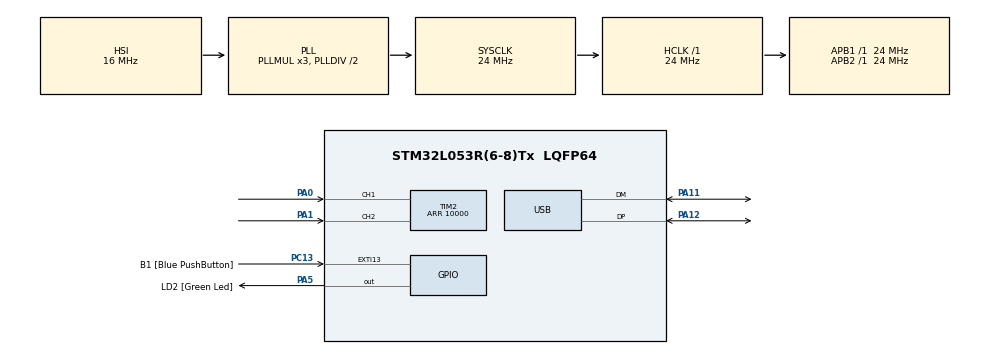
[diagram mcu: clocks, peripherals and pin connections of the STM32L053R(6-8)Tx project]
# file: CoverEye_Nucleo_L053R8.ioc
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Mcu.Family=STM32L0
Mcu.Name=STM32L053R(6-8)Tx
Mcu.Package=LQFP64
NVIC.USB_IRQn=true\:0\:0\:false\:false\:true\:false
PA0.GPIO_PuPd=GPIO_PULLDOWN
PA0.GPIO_Speed=GPIO_SPEED_FREQ_VERY_HIGH
PA0.Signal=S_TIM2_CH1
PA1.GPIO_PuPd=GPIO_PULLDOWN
PA1.GPIO_Speed=GPIO_SPEED_FREQ_VERY_HIGH
PA1.Signal=S_TIM2_CH2
PA11.Mode=Device
PA11.Signal=USB_DM
PA12.Mode=Device
PA12.Signal=USB_DP
PA13.GPIO_Label=TMS
PA13.Signal=SYS_SWDIO
PA14.GPIO_Label=TCK
PA14.Signal=SYS_SWCLK
PA2.GPIO_Label=USART_TX
PA2.Signal=USART2_TX
PA3.GPIO_Label=USART_RX
PA3.Signal=USART2_RX
PA5.GPIO_Label=LD2 [Green Led]
PA5.Signal=GPIO_Output
PC13.GPIO_Label=B1 [Blue PushButton]
PC13.GPIO_ModeDefaultEXTI=GPIO_MODE_IT_FALLING
PC13.Signal=GPXTI13
PC14-OSC32_IN.Signal=RCC_OSC32_IN
PC15-OSC32_OUT.Signal=RCC_OSC32_OUT
PH0-OSC_IN.Signal=RCC_OSC_IN
PH1-OSC_OUT.Signal=RCC_OSC_OUT
ProjectManager.HeapSize=0x200
ProjectManager.StackSize=0x400
ProjectManager.TargetToolchain=SW4STM32
RCC.AHBFreq_Value=24000000
RCC.APB1Freq_Value=24000000
RCC.APB1TimFreq_Value=24000000
RCC.APB2Freq_Value=24000000
RCC.APB2TimFreq_Value=24000000
RCC.HCLKFreq_Value=24000000
RCC.HSE_VALUE=8000000
RCC.HSI16_VALUE=16000000
RCC.HSI48MClockSelection=RCC_USBCLKSOURCE_HSI48
RCC.HSI48_VALUE=48000000
RCC.HSI_VALUE=16000000
RCC.LSEState=RCC_LSE_ON
RCC.LSE_VALUE=32768
RCC.MSI_VALUE=2097000
RCC.SYSCLKFreq_VALUE=24000000
RCC.SYSCLKSource=RCC_SYSCLKSOURCE_PLLCLK
RCC.VCOOutputFreq_Value=48000000
SH.S_TIM2_CH1.0=TIM2_CH1,Encoder_Interface
SH.S_TIM2_CH2.0=TIM2_CH2,Encoder_Interface
TIM2.IC2Filter=0
TIM2.Period=10000
USB_DEVICE.CLASS_NAME_FS=CUSTOMHID
USB_DEVICE.VirtualMode=CustomHid
USB_DEVICE.VirtualModeFS=Custom_Hid_FS
VP_USB_DEVICE_VS_USB_DEVICE_CUSTOM_HID_FS.Mode=CUSTOM_HID_FS
board=NUCLEO-L053R8

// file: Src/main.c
/**
  ******************************************************************************
  * File Name          : main.c
  * Description        : Main program body
  ******************************************************************************
  * This notice applies to any and all portions of this file
  * that are not between comment pairs USER CODE BEGIN and
  * USER CODE END. Other portions of this file, whether
  * inserted by the user or by software development tools
  * are owned by their respective copyright owners.
  *
  * Copyright (c) 2018 STMicroelectronics International N.V.
  * All rights reserved.
  *
  * Redistribution and use in source and binary forms, with or without
  * modification, are permitted, provided that the following conditions are met:
  *
  * 1. Redistribution of source code must retain the above copyright notice,
  *    this list of conditions and the following disclaimer.
  * 2. Redistributions in binary form must reproduce the above copyright notice,
  *    this list of conditions and the following disclaimer in the documentation
  *    and/or other materials provided with the distribution.
  * 3. Neither the name of STMicroelectronics nor the names of other
  *    contributors to this software may be used to endorse or promote products
  *    derived from this software without specific written permission.
  * 4. This software, including modifications and/or derivative works of this
  *    software, must execute solely and exclusively on microcontroller or
  *    microprocessor devices manufactured by or for STMicroelectronics.
  * 5. Redistribution and use of this software other than as permitted under
  *    this license is void and will automatically terminate your rights under
  *    this license.
  *
  * THIS SOFTWARE IS PROVIDED BY STMICROELECTRONICS AND CONTRIBUTORS "AS IS"
  * AND ANY EXPRESS, IMPLIED OR STATUTORY WARRANTIES, INCLUDING, BUT NOT
  * LIMITED TO, THE IMPLIED WARRANTIES OF MERCHANTABILITY, FITNESS FOR A
  * PARTICULAR PURPOSE AND NON-INFRINGEMENT OF THIRD PARTY INTELLECTUAL PROPERTY
  * RIGHTS ARE DISCLAIMED TO THE FULLEST EXTENT PERMITTED BY LAW. IN NO EVENT
  * SHALL STMICROELECTRONICS OR CONTRIBUTORS BE LIABLE FOR ANY DIRECT, INDIRECT,
  * INCIDENTAL, SPECIAL, EXEMPLARY, OR CONSEQUENTIAL DAMAGES (INCLUDING, BUT NOT
  * LIMITED TO, PROCUREMENT OF SUBSTITUTE GOODS OR SERVICES; LOSS OF USE, DATA,
  * OR PROFITS; OR BUSINESS INTERRUPTION) HOWEVER CAUSED AND ON ANY THEORY OF
  * LIABILITY, WHETHER IN CONTRACT, STRICT LIABILITY, OR TORT (INCLUDING
  * NEGLIGENCE OR OTHERWISE) ARISING IN ANY WAY OUT OF THE USE OF THIS SOFTWARE,
  * EVEN IF ADVISED OF THE POSSIBILITY OF SUCH DAMAGE.
  *
  ******************************************************************************
  */

#include "main.h"
#include "stm32l0xx_hal.h"
#include "usb_device.h"
#include "usbd_core.h"
#include "usbd_customhid.h"

TIM_HandleTypeDef htim2;
int count;

// HID testDPControl
  /*struct testDPControlHID_t {
      uint8_t id;
      uint8_t modifiers;
      uint8_t key1;
      uint8_t key2;
      uint8_t key3;
  };*/
//uint8_t *ptestDPControl;
//uint8_t testDPControl=0x777;

  //struct testDPControlHID_t testDPControlHID;

USBD_StatusTypeDef status;
/* USER CODE BEGIN PV */
/* Private variables ---------------------------------------------------------*/

/* USER CODE END PV */

void SystemClock_Config(void);
static void MX_GPIO_Init(void);
static void MX_TIM2_Init(void);

/* USER CODE BEGIN PFP */
/* Private function prototypes -----------------------------------------------*/

/* USER CODE END PFP */

int main(void)
{
	/*testDPControlHID.id = 0x1;
	testDPControlHID.modifiers = 0x2;
	testDPControlHID.key1 = 0x3;
	testDPControlHID.key2 = 0x4;
	testDPControlHID.key3 = 0x5;*/

  /* MCU Configuration----------------------------------------------------------*/

  /* Reset of all peripherals, Initializes the Flash interface and the Systick. */
  HAL_Init();

  /* Configure the system clock */
  SystemClock_Config();

  /* USER CODE BEGIN SysInit */
  //USBD_Init(&hUsbDeviceFS, &FS_Desc, DEVICE_FS);
  //USBD_StatusTypeDef USBD_Init(USBD_HandleTypeDef *pdev, USBD_DescriptorsTypeDef *pdesc, uint8_t id)

  //SBD_RegisterClass(&hUsbDeviceFS, &USBD_CUSTOM_HID);
  //USBD_StatusTypeDef  USBD_RegisterClass(USBD_HandleTypeDef *pdev, USBD_ClassTypeDef *pclass)

  //USBD_CUSTOM_HID_RegisterInterface(&hUsbDeviceFS, &USBD_CustomHID_fops_FS);
  //uint8_t  USBD_CUSTOM_HID_RegisterInterface  (USBD_HandleTypeDef   *pdev,
   //                                            USBD_CUSTOM_HID_ItfTypeDef *fops)

  //USBD_Start(&hUsbDeviceFS);
  /* USER CODE END SysInit */

  /* Initialize all configured peripherals */
  MX_GPIO_Init();
  MX_USB_DEVICE_Init();
  MX_TIM2_Init();
  HAL_TIM_Encoder_MspInit(&htim2);
  HAL_TIM_Encoder_Start(&htim2,TIM_CHANNEL_1);

  /* Infinite loop */
  while (1)
  {
	 count = __HAL_TIM_GetCounter(&htim2);

	 //uint8_t result = USBD_CUSTOM_HID_SendReport(&hUsbDeviceFS,&testDPControl,sizeof(testDPControl));

	 //HAL_Delay(500);

	 //status= USBD_LL_DataOutStage(&hUsbDeviceFS,4,);
	 //USBD_LL_DataOutStage(USBD_HandleTypeDef *pdev , uint8_t epnum, uint8_t *pdata)
  }

}

/** System Clock Configuration
*/
void SystemClock_Config(void)
{

  RCC_OscInitTypeDef RCC_OscInitStruct;
  RCC_ClkInitTypeDef RCC_ClkInitStruct;
  RCC_PeriphCLKInitTypeDef PeriphClkInit;

    /**Configure the main internal regulator output voltage
    */
  __HAL_PWR_VOLTAGESCALING_CONFIG(PWR_REGULATOR_VOLTAGE_SCALE1);

    /**Initializes the CPU, AHB and APB busses clocks
    */
  RCC_OscInitStruct.OscillatorType = RCC_OSCILLATORTYPE_HSI|RCC_OSCILLATORTYPE_HSI48;
  RCC_OscInitStruct.HSIState = RCC_HSI_ON;
  RCC_OscInitStruct.HSICalibrationValue = 16;
  RCC_OscInitStruct.HSI48State = RCC_HSI48_ON;
  RCC_OscInitStruct.PLL.PLLState = RCC_PLL_ON;
  RCC_OscInitStruct.PLL.PLLSource = RCC_PLLSOURCE_HSI;
  RCC_OscInitStruct.PLL.PLLMUL = RCC_PLLMUL_3;
  RCC_OscInitStruct.PLL.PLLDIV = RCC_PLLDIV_2;
  if (HAL_RCC_OscConfig(&RCC_OscInitStruct) != HAL_OK)
  {
    _Error_Handler(__FILE__, __LINE__);
  }

    /**Initializes the CPU, AHB and APB busses clocks
    */
  RCC_ClkInitStruct.ClockType = RCC_CLOCKTYPE_HCLK|RCC_CLOCKTYPE_SYSCLK
                              |RCC_CLOCKTYPE_PCLK1|RCC_CLOCKTYPE_PCLK2;
  RCC_ClkInitStruct.SYSCLKSource = RCC_SYSCLKSOURCE_PLLCLK;
  RCC_ClkInitStruct.AHBCLKDivider = RCC_SYSCLK_DIV1;
  RCC_ClkInitStruct.APB1CLKDivider = RCC_HCLK_DIV1;
  RCC_ClkInitStruct.APB2CLKDivider = RCC_HCLK_DIV1;

  if (HAL_RCC_ClockConfig(&RCC_ClkInitStruct, FLASH_LATENCY_1) != HAL_OK)
  {
    _Error_Handler(__FILE__, __LINE__);
  }

  PeriphClkInit.PeriphClockSelection = RCC_PERIPHCLK_USB;
  PeriphClkInit.UsbClockSelection = RCC_USBCLKSOURCE_HSI48;
  if (HAL_RCCEx_PeriphCLKConfig(&PeriphClkInit) != HAL_OK)
  {
    _Error_Handler(__FILE__, __LINE__);
  }

    /**Configure the Systick interrupt time
    */
  HAL_SYSTICK_Config(HAL_RCC_GetHCLKFreq()/1000);

    /**Configure the Systick
    */
  HAL_SYSTICK_CLKSourceConfig(SYSTICK_CLKSOURCE_HCLK);

  /* SysTick_IRQn interrupt configuration */
  HAL_NVIC_SetPriority(SysTick_IRQn, 0, 0);
}

/* TIM2 init function */
static void MX_TIM2_Init(void)
{

  TIM_Encoder_InitTypeDef sConfig;
  TIM_MasterConfigTypeDef sMasterConfig;

  htim2.Instance = TIM2;
  htim2.Init.Prescaler = 0;
  htim2.Init.CounterMode = TIM_COUNTERMODE_UP;
  htim2.Init.Period = 10000;
  htim2.Init.ClockDivision = TIM_CLOCKDIVISION_DIV1;
  sConfig.EncoderMode = TIM_ENCODERMODE_TI1;
  sConfig.IC1Polarity = TIM_ICPOLARITY_RISING;
  sConfig.IC1Selection = TIM_ICSELECTION_DIRECTTI;
  sConfig.IC1Prescaler = TIM_ICPSC_DIV1;
  sConfig.IC1Filter = 0;
  sConfig.IC2Polarity = TIM_ICPOLARITY_RISING;
  sConfig.IC2Selection = TIM_ICSELECTION_DIRECTTI;
  sConfig.IC2Prescaler = TIM_ICPSC_DIV1;
  sConfig.IC2Filter = 0;
  if (HAL_TIM_Encoder_Init(&htim2, &sConfig) != HAL_OK)
  {
    _Error_Handler(__FILE__, __LINE__);
  }

  sMasterConfig.MasterOutputTrigger = TIM_TRGO_RESET;
  sMasterConfig.MasterSlaveMode = TIM_MASTERSLAVEMODE_DISABLE;
  if (HAL_TIMEx_MasterConfigSynchronization(&htim2, &sMasterConfig) != HAL_OK)
  {
    _Error_Handler(__FILE__, __LINE__);
  }

}

/** Configure pins as
        * Analog
        * Input
        * Output
        * EVENT_OUT
        * EXTI
     PA2   ------> USART2_TX
     PA3   ------> USART2_RX
*/
static void MX_GPIO_Init(void)
{

  GPIO_InitTypeDef GPIO_InitStruct;

  /* GPIO Ports Clock Enable */
  __HAL_RCC_GPIOC_CLK_ENABLE();
  __HAL_RCC_GPIOH_CLK_ENABLE();
  __HAL_RCC_GPIOA_CLK_ENABLE();

  /*Configure GPIO pin Output Level */
  HAL_GPIO_WritePin(LD2_GPIO_Port, LD2_Pin, GPIO_PIN_RESET);

  /*Configure GPIO pin : B1_Pin */
  GPIO_InitStruct.Pin = B1_Pin;
  GPIO_InitStruct.Mode = GPIO_MODE_IT_FALLING;
  GPIO_InitStruct.Pull = GPIO_NOPULL;
  HAL_GPIO_Init(B1_GPIO_Port, &GPIO_InitStruct);

  /*Configure GPIO pins : USART_TX_Pin USART_RX_Pin */
  GPIO_InitStruct.Pin = USART_TX_Pin|USART_RX_Pin;
  GPIO_InitStruct.Mode = GPIO_MODE_AF_PP;
  GPIO_InitStruct.Pull = GPIO_NOPULL;
  GPIO_InitStruct.Speed = GPIO_SPEED_FREQ_VERY_HIGH;
  GPIO_InitStruct.Alternate = GPIO_AF4_USART2;
  HAL_GPIO_Init(GPIOA, &GPIO_InitStruct);

  /*Configure GPIO pin : LD2_Pin */
  GPIO_InitStruct.Pin = LD2_Pin;
  GPIO_InitStruct.Mode = GPIO_MODE_OUTPUT_PP;
  GPIO_InitStruct.Pull = GPIO_NOPULL;
  GPIO_InitStruct.Speed = GPIO_SPEED_FREQ_LOW;
  HAL_GPIO_Init(LD2_GPIO_Port, &GPIO_InitStruct);

}

void _Error_Handler(char * file, int line)
{
  while(1)
  {
  }
}

/************************ (C) COPYRIGHT STMicroelectronics *****END OF FILE****/
